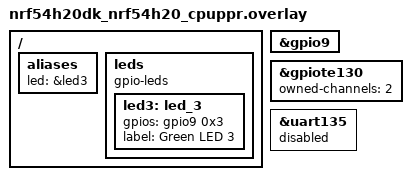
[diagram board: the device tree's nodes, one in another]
/*
 * Copyright (c) 2026 Nordic Semiconductor ASA
 *
 * SPDX-License-Identifier: LicenseRef-Nordic-5-Clause
 */

/ {
	aliases {
		led = &led3;
	};

	leds {
		compatible = "gpio-leds";

		led3: led_3 {
			gpios = <&gpio9 0x3 0x0>;
			label = "Green LED 3";
		};
	};
};

&gpio9 {
	status = "okay";
};

&gpiote130 {
	status = "okay";
	owned-channels = <2>;
};

/* UART135 is owned by Radio core. */
&uart135 {
	status = "disabled";
};
